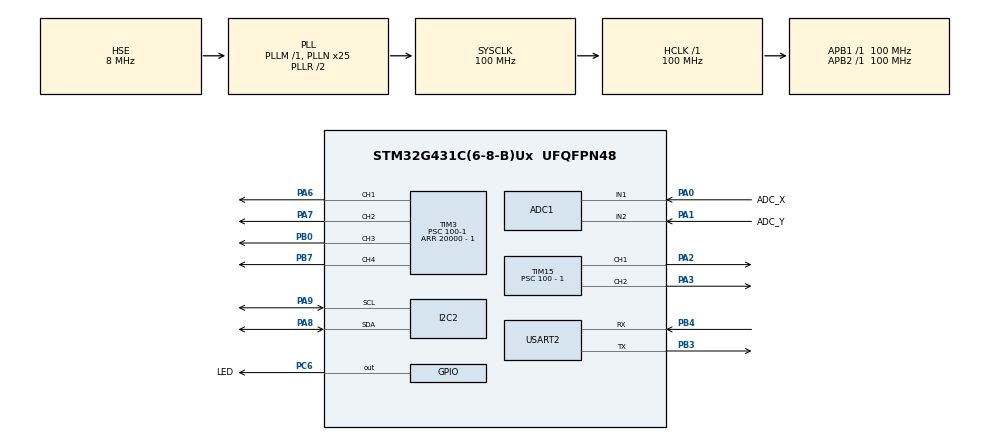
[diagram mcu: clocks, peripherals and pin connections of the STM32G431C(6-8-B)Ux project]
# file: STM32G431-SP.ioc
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ADC1.Channel-0\#ChannelRegularConversion=ADC_CHANNEL_1
ADC1.NbrOfConversionFlag=1
ADC1.OffsetNumber-0\#ChannelRegularConversion=ADC_OFFSET_NONE
ADC1.Rank-0\#ChannelRegularConversion=1
ADC1.SamplingTime-0\#ChannelRegularConversion=ADC_SAMPLETIME_2CYCLES_5
ADC1.master=1
I2C2.Timing=0x10C0ECFF
Mcu.Family=STM32G4
Mcu.Name=STM32G431C(6-8-B)Ux
Mcu.Package=UFQFPN48
Mcu.UserConstants=HCLK_VAL,100
NVIC.PriorityGroup=NVIC_PRIORITYGROUP_4
NVIC.TIM7_IRQn=true\:15\:0\:false\:false\:true\:false\:true\:true
NVIC.TimeBase=TIM7_IRQn
NVIC.TimeBaseIP=TIM7
NVIC.USART2_IRQn=true\:0\:0\:false\:false\:true\:true\:true\:true
PA0.GPIO_Label=ADC_X
PA0.Mode=IN1-Single-Ended
PA0.Signal=ADC1_IN1
PA1.GPIO_Label=ADC_Y
PA1.Mode=IN2-Single-Ended
PA1.Signal=ADC1_IN2
PA13.Mode=Serial_Wire
PA13.Signal=SYS_JTMS-SWDIO
PA14.Mode=Serial_Wire
PA14.Signal=SYS_JTCK-SWCLK
PA2.Signal=S_TIM15_CH1
PA3.Signal=S_TIM15_CH2
PA6.Signal=S_TIM3_CH1
PA7.Signal=S_TIM3_CH2
PA8.Mode=I2C
PA8.Signal=I2C2_SDA
PA9.Mode=I2C
PA9.Signal=I2C2_SCL
PB0.Signal=S_TIM3_CH3
PB3.Mode=Asynchronous
PB3.Signal=USART2_TX
PB4.Mode=Asynchronous
PB4.Signal=USART2_RX
PB7.Signal=S_TIM3_CH4
PC6.GPIO_Label=LED
PC6.Signal=GPIO_Output
PF0-OSC_IN.Mode=HSE-External-Oscillator
PF0-OSC_IN.Signal=RCC_OSC_IN
PF1-OSC_OUT.Mode=HSE-External-Oscillator
PF1-OSC_OUT.Signal=RCC_OSC_OUT
ProjectManager.HeapSize=0x200
ProjectManager.StackSize=0x400
ProjectManager.TargetToolchain=Makefile
RCC.ADC12Freq_Value=100000000
RCC.AHBFreq_Value=100000000
RCC.APB1Freq_Value=100000000
RCC.APB1TimFreq_Value=100000000
RCC.APB2Freq_Value=100000000
RCC.APB2TimFreq_Value=100000000
RCC.CortexFreq_Value=100000000
RCC.EXTERNAL_CLOCK_VALUE=12288000
RCC.HCLKFreq_Value=100000000
RCC.HSE_VALUE=8000000
RCC.HSI48_VALUE=48000000
RCC.HSI_VALUE=16000000
RCC.LSE_VALUE=32768
RCC.PLLN=25
RCC.PLLSourceVirtual=RCC_PLLSOURCE_HSE
RCC.SYSCLKFreq_VALUE=100000000
RCC.SYSCLKSource=RCC_SYSCLKSOURCE_PLLCLK
RCC.USBFreq_Value=100000000
RCC.VCOOutputFreq_Value=200000000
SH.S_TIM15_CH1.0=TIM15_CH1,PWM Generation1 CH1
SH.S_TIM15_CH2.0=TIM15_CH2,PWM Generation2 CH2
SH.S_TIM3_CH1.0=TIM3_CH1,PWM Generation1 CH1
SH.S_TIM3_CH2.0=TIM3_CH2,PWM Generation2 CH2
SH.S_TIM3_CH3.0=TIM3_CH3,PWM Generation3 CH3
SH.S_TIM3_CH4.0=TIM3_CH4,PWM Generation4 CH4
TIM15.Channel-PWM\ Generation1\ CH1=TIM_CHANNEL_1
TIM15.Channel-PWM\ Generation2\ CH2=TIM_CHANNEL_2
TIM15.PeriodNoDither=20000 - 1
TIM15.Prescaler=100 - 1
TIM3.Channel-PWM\ Generation1\ CH1=TIM_CHANNEL_1
TIM3.Channel-PWM\ Generation2\ CH2=TIM_CHANNEL_2
TIM3.Channel-PWM\ Generation3\ CH3=TIM_CHANNEL_3
TIM3.Channel-PWM\ Generation4\ CH4=TIM_CHANNEL_4
TIM3.PeriodNoDither=20000 - 1
TIM3.Prescaler=100-1
USART2.VirtualMode-Asynchronous=VM_ASYNC
VP_SYS_VS_DBSignals.Mode=DisableDeadBatterySignals
VP_SYS_VS_tim7.Mode=TIM7
VP_TIM15_VS_ClockSourceINT.Mode=Internal
VP_TIM3_VS_ClockSourceINT.Mode=Internal
board=custom

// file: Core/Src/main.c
/* USER CODE BEGIN Header */
/**
  ******************************************************************************
  * @file           : main.c
  * @brief          : Main program body
  ******************************************************************************
  * @attention
  *
  * Copyright (c) 2023 STMicroelectronics.
  * All rights reserved.
  *
  * This software is licensed under terms that can be found in the LICENSE file
  * in the root directory of this software component.
  * If no LICENSE file comes with this software, it is provided AS-IS.
  *
  ******************************************************************************
  */
/* USER CODE END Header */
#include "main.h"

/* USER CODE BEGIN Includes */
#include "app.hpp"
/* USER CODE END Includes */

ADC_HandleTypeDef hadc1;

I2C_HandleTypeDef hi2c2;

TIM_HandleTypeDef htim3;
TIM_HandleTypeDef htim15;

UART_HandleTypeDef huart2;

void SystemClock_Config(void);
static void MX_GPIO_Init(void);
static void MX_TIM3_Init(void);
static void MX_ADC1_Init(void);
static void MX_TIM15_Init(void);
static void MX_I2C2_Init(void);
static void MX_USART2_UART_Init(void);

int main(void)
{

  /* MCU Configuration--------------------------------------------------------*/

  /* Reset of all peripherals, Initializes the Flash interface and the Systick. */
  HAL_Init();

  /* Configure the system clock */
  SystemClock_Config();

  /* Initialize all configured peripherals */
  MX_GPIO_Init();
  MX_TIM3_Init();
  MX_ADC1_Init();
  MX_TIM15_Init();
  MX_I2C2_Init();
  MX_USART2_UART_Init();
  /* USER CODE BEGIN 2 */
  app_c();
  /* USER CODE END 2 */

  /* Infinite loop */
  while (1)
  {

  }
}

void SystemClock_Config(void)
{
  RCC_OscInitTypeDef RCC_OscInitStruct = {0};
  RCC_ClkInitTypeDef RCC_ClkInitStruct = {0};

  /** Configure the main internal regulator output voltage
  */
  HAL_PWREx_ControlVoltageScaling(PWR_REGULATOR_VOLTAGE_SCALE1);

  /** Initializes the RCC Oscillators according to the specified parameters
  * in the RCC_OscInitTypeDef structure.
  */
  RCC_OscInitStruct.OscillatorType = RCC_OSCILLATORTYPE_HSE;
  RCC_OscInitStruct.HSEState = RCC_HSE_ON;
  RCC_OscInitStruct.PLL.PLLState = RCC_PLL_ON;
  RCC_OscInitStruct.PLL.PLLSource = RCC_PLLSOURCE_HSE;
  RCC_OscInitStruct.PLL.PLLM = RCC_PLLM_DIV1;
  RCC_OscInitStruct.PLL.PLLN = 25;
  RCC_OscInitStruct.PLL.PLLP = RCC_PLLP_DIV2;
  RCC_OscInitStruct.PLL.PLLQ = RCC_PLLQ_DIV2;
  RCC_OscInitStruct.PLL.PLLR = RCC_PLLR_DIV2;
  if (HAL_RCC_OscConfig(&RCC_OscInitStruct) != HAL_OK)
  {
    Error_Handler();
  }

  /** Initializes the CPU, AHB and APB buses clocks
  */
  RCC_ClkInitStruct.ClockType = RCC_CLOCKTYPE_HCLK|RCC_CLOCKTYPE_SYSCLK
                              |RCC_CLOCKTYPE_PCLK1|RCC_CLOCKTYPE_PCLK2;
  RCC_ClkInitStruct.SYSCLKSource = RCC_SYSCLKSOURCE_PLLCLK;
  RCC_ClkInitStruct.AHBCLKDivider = RCC_SYSCLK_DIV1;
  RCC_ClkInitStruct.APB1CLKDivider = RCC_HCLK_DIV1;
  RCC_ClkInitStruct.APB2CLKDivider = RCC_HCLK_DIV1;

  if (HAL_RCC_ClockConfig(&RCC_ClkInitStruct, FLASH_LATENCY_3) != HAL_OK)
  {
    Error_Handler();
  }
}

static void MX_ADC1_Init(void)
{

  ADC_MultiModeTypeDef multimode = {0};
  ADC_ChannelConfTypeDef sConfig = {0};

  /** Common config
  */
  hadc1.Instance = ADC1;
  hadc1.Init.ClockPrescaler = ADC_CLOCK_SYNC_PCLK_DIV2;
  hadc1.Init.Resolution = ADC_RESOLUTION_12B;
  hadc1.Init.DataAlign = ADC_DATAALIGN_RIGHT;
  hadc1.Init.GainCompensation = 0;
  hadc1.Init.ScanConvMode = ADC_SCAN_DISABLE;
  hadc1.Init.EOCSelection = ADC_EOC_SINGLE_CONV;
  hadc1.Init.LowPowerAutoWait = DISABLE;
  hadc1.Init.ContinuousConvMode = DISABLE;
  hadc1.Init.NbrOfConversion = 1;
  hadc1.Init.DiscontinuousConvMode = DISABLE;
  hadc1.Init.ExternalTrigConv = ADC_SOFTWARE_START;
  hadc1.Init.ExternalTrigConvEdge = ADC_EXTERNALTRIGCONVEDGE_NONE;
  hadc1.Init.DMAContinuousRequests = DISABLE;
  hadc1.Init.Overrun = ADC_OVR_DATA_PRESERVED;
  hadc1.Init.OversamplingMode = DISABLE;
  if (HAL_ADC_Init(&hadc1) != HAL_OK)
  {
    Error_Handler();
  }

  /** Configure the ADC multi-mode
  */
  multimode.Mode = ADC_MODE_INDEPENDENT;
  if (HAL_ADCEx_MultiModeConfigChannel(&hadc1, &multimode) != HAL_OK)
  {
    Error_Handler();
  }

  /** Configure Regular Channel
  */
  sConfig.Channel = ADC_CHANNEL_1;
  sConfig.Rank = ADC_REGULAR_RANK_1;
  sConfig.SamplingTime = ADC_SAMPLETIME_2CYCLES_5;
  sConfig.SingleDiff = ADC_SINGLE_ENDED;
  sConfig.OffsetNumber = ADC_OFFSET_NONE;
  sConfig.Offset = 0;
  if (HAL_ADC_ConfigChannel(&hadc1, &sConfig) != HAL_OK)
  {
    Error_Handler();
  }

}

static void MX_I2C2_Init(void)
{

  hi2c2.Instance = I2C2;
  hi2c2.Init.Timing = 0x10C0ECFF;
  hi2c2.Init.OwnAddress1 = 0;
  hi2c2.Init.AddressingMode = I2C_ADDRESSINGMODE_7BIT;
  hi2c2.Init.DualAddressMode = I2C_DUALADDRESS_DISABLE;
  hi2c2.Init.OwnAddress2 = 0;
  hi2c2.Init.OwnAddress2Masks = I2C_OA2_NOMASK;
  hi2c2.Init.GeneralCallMode = I2C_GENERALCALL_DISABLE;
  hi2c2.Init.NoStretchMode = I2C_NOSTRETCH_DISABLE;
  if (HAL_I2C_Init(&hi2c2) != HAL_OK)
  {
    Error_Handler();
  }

  /** Configure Analogue filter
  */
  if (HAL_I2CEx_ConfigAnalogFilter(&hi2c2, I2C_ANALOGFILTER_ENABLE) != HAL_OK)
  {
    Error_Handler();
  }

  /** Configure Digital filter
  */
  if (HAL_I2CEx_ConfigDigitalFilter(&hi2c2, 0) != HAL_OK)
  {
    Error_Handler();
  }

}

static void MX_TIM3_Init(void)
{

  TIM_ClockConfigTypeDef sClockSourceConfig = {0};
  TIM_MasterConfigTypeDef sMasterConfig = {0};
  TIM_OC_InitTypeDef sConfigOC = {0};

  htim3.Instance = TIM3;
  htim3.Init.Prescaler = 100-1;
  htim3.Init.CounterMode = TIM_COUNTERMODE_UP;
  htim3.Init.Period = 19999;
  htim3.Init.ClockDivision = TIM_CLOCKDIVISION_DIV1;
  htim3.Init.AutoReloadPreload = TIM_AUTORELOAD_PRELOAD_DISABLE;
  if (HAL_TIM_Base_Init(&htim3) != HAL_OK)
  {
    Error_Handler();
  }
  sClockSourceConfig.ClockSource = TIM_CLOCKSOURCE_INTERNAL;
  if (HAL_TIM_ConfigClockSource(&htim3, &sClockSourceConfig) != HAL_OK)
  {
    Error_Handler();
  }
  if (HAL_TIM_PWM_Init(&htim3) != HAL_OK)
  {
    Error_Handler();
  }
  sMasterConfig.MasterOutputTrigger = TIM_TRGO_RESET;
  sMasterConfig.MasterSlaveMode = TIM_MASTERSLAVEMODE_DISABLE;
  if (HAL_TIMEx_MasterConfigSynchronization(&htim3, &sMasterConfig) != HAL_OK)
  {
    Error_Handler();
  }
  sConfigOC.OCMode = TIM_OCMODE_PWM1;
  sConfigOC.Pulse = 0;
  sConfigOC.OCPolarity = TIM_OCPOLARITY_HIGH;
  sConfigOC.OCFastMode = TIM_OCFAST_DISABLE;
  if (HAL_TIM_PWM_ConfigChannel(&htim3, &sConfigOC, TIM_CHANNEL_1) != HAL_OK)
  {
    Error_Handler();
  }
  if (HAL_TIM_PWM_ConfigChannel(&htim3, &sConfigOC, TIM_CHANNEL_2) != HAL_OK)
  {
    Error_Handler();
  }
  if (HAL_TIM_PWM_ConfigChannel(&htim3, &sConfigOC, TIM_CHANNEL_3) != HAL_OK)
  {
    Error_Handler();
  }
  if (HAL_TIM_PWM_ConfigChannel(&htim3, &sConfigOC, TIM_CHANNEL_4) != HAL_OK)
  {
    Error_Handler();
  }
  HAL_TIM_MspPostInit(&htim3);

}

static void MX_TIM15_Init(void)
{

  TIM_ClockConfigTypeDef sClockSourceConfig = {0};
  TIM_MasterConfigTypeDef sMasterConfig = {0};
  TIM_OC_InitTypeDef sConfigOC = {0};
  TIM_BreakDeadTimeConfigTypeDef sBreakDeadTimeConfig = {0};

  htim15.Instance = TIM15;
  htim15.Init.Prescaler = 100 - 1;
  htim15.Init.CounterMode = TIM_COUNTERMODE_UP;
  htim15.Init.Period = 19999;
  htim15.Init.ClockDivision = TIM_CLOCKDIVISION_DIV1;
  htim15.Init.RepetitionCounter = 0;
  htim15.Init.AutoReloadPreload = TIM_AUTORELOAD_PRELOAD_DISABLE;
  if (HAL_TIM_Base_Init(&htim15) != HAL_OK)
  {
    Error_Handler();
  }
  sClockSourceConfig.ClockSource = TIM_CLOCKSOURCE_INTERNAL;
  if (HAL_TIM_ConfigClockSource(&htim15, &sClockSourceConfig) != HAL_OK)
  {
    Error_Handler();
  }
  if (HAL_TIM_PWM_Init(&htim15) != HAL_OK)
  {
    Error_Handler();
  }
  sMasterConfig.MasterOutputTrigger = TIM_TRGO_RESET;
  sMasterConfig.MasterSlaveMode = TIM_MASTERSLAVEMODE_DISABLE;
  if (HAL_TIMEx_MasterConfigSynchronization(&htim15, &sMasterConfig) != HAL_OK)
  {
    Error_Handler();
  }
  sConfigOC.OCMode = TIM_OCMODE_PWM1;
  sConfigOC.Pulse = 0;
  sConfigOC.OCPolarity = TIM_OCPOLARITY_HIGH;
  sConfigOC.OCNPolarity = TIM_OCNPOLARITY_HIGH;
  sConfigOC.OCFastMode = TIM_OCFAST_DISABLE;
  sConfigOC.OCIdleState = TIM_OCIDLESTATE_RESET;
  sConfigOC.OCNIdleState = TIM_OCNIDLESTATE_RESET;
  if (HAL_TIM_PWM_ConfigChannel(&htim15, &sConfigOC, TIM_CHANNEL_1) != HAL_OK)
  {
    Error_Handler();
  }
  if (HAL_TIM_PWM_ConfigChannel(&htim15, &sConfigOC, TIM_CHANNEL_2) != HAL_OK)
  {
    Error_Handler();
  }
  sBreakDeadTimeConfig.OffStateRunMode = TIM_OSSR_DISABLE;
  sBreakDeadTimeConfig.OffStateIDLEMode = TIM_OSSI_DISABLE;
  sBreakDeadTimeConfig.LockLevel = TIM_LOCKLEVEL_OFF;
  sBreakDeadTimeConfig.DeadTime = 0;
  sBreakDeadTimeConfig.BreakState = TIM_BREAK_DISABLE;
  sBreakDeadTimeConfig.BreakPolarity = TIM_BREAKPOLARITY_HIGH;
  sBreakDeadTimeConfig.BreakFilter = 0;
  sBreakDeadTimeConfig.AutomaticOutput = TIM_AUTOMATICOUTPUT_DISABLE;
  if (HAL_TIMEx_ConfigBreakDeadTime(&htim15, &sBreakDeadTimeConfig) != HAL_OK)
  {
    Error_Handler();
  }
  HAL_TIM_MspPostInit(&htim15);

}

static void MX_USART2_UART_Init(void)
{

  huart2.Instance = USART2;
  huart2.Init.BaudRate = 115200;
  huart2.Init.WordLength = UART_WORDLENGTH_8B;
  huart2.Init.StopBits = UART_STOPBITS_1;
  huart2.Init.Parity = UART_PARITY_NONE;
  huart2.Init.Mode = UART_MODE_TX_RX;
  huart2.Init.HwFlowCtl = UART_HWCONTROL_NONE;
  huart2.Init.OverSampling = UART_OVERSAMPLING_16;
  huart2.Init.OneBitSampling = UART_ONE_BIT_SAMPLE_DISABLE;
  huart2.Init.ClockPrescaler = UART_PRESCALER_DIV1;
  huart2.AdvancedInit.AdvFeatureInit = UART_ADVFEATURE_NO_INIT;
  if (HAL_UART_Init(&huart2) != HAL_OK)
  {
    Error_Handler();
  }
  if (HAL_UARTEx_SetTxFifoThreshold(&huart2, UART_TXFIFO_THRESHOLD_1_8) != HAL_OK)
  {
    Error_Handler();
  }
  if (HAL_UARTEx_SetRxFifoThreshold(&huart2, UART_RXFIFO_THRESHOLD_1_8) != HAL_OK)
  {
    Error_Handler();
  }
  if (HAL_UARTEx_DisableFifoMode(&huart2) != HAL_OK)
  {
    Error_Handler();
  }

}

static void MX_GPIO_Init(void)
{
  GPIO_InitTypeDef GPIO_InitStruct = {0};

  /* GPIO Ports Clock Enable */
  __HAL_RCC_GPIOF_CLK_ENABLE();
  __HAL_RCC_GPIOA_CLK_ENABLE();
  __HAL_RCC_GPIOB_CLK_ENABLE();
  __HAL_RCC_GPIOC_CLK_ENABLE();

  /*Configure GPIO pin Output Level */
  HAL_GPIO_WritePin(LED_GPIO_Port, LED_Pin, GPIO_PIN_RESET);

  /*Configure GPIO pin : LED_Pin */
  GPIO_InitStruct.Pin = LED_Pin;
  GPIO_InitStruct.Mode = GPIO_MODE_OUTPUT_PP;
  GPIO_InitStruct.Pull = GPIO_NOPULL;
  GPIO_InitStruct.Speed = GPIO_SPEED_FREQ_LOW;
  HAL_GPIO_Init(LED_GPIO_Port, &GPIO_InitStruct);

}

void HAL_TIM_PeriodElapsedCallback(TIM_HandleTypeDef *htim)
{
  if (htim->Instance == TIM7) {
    HAL_IncTick();
  }
}

void Error_Handler(void)
{
  __disable_irq();
  while (1)
  {
  }
}
